# ET6801 register map
Vendor: ETMCU Inc.; File version: v0.0.1
CPU: CM7 r2p1, little endian, MPU, FPU, I-cache, D-cache, ITCM, DTCM, 4 interrupt priority bits
Registers are 32-bit, read-write, reset 0x0 unless marked. A register's access mark holds for its fields unless they carry their own. Offsets are from the block's base; [hi:lo] are bit positions; 'fields as' and 'values as' point back to an identical list.

## CORDIC — Provide an overview of the purpose and functionality of the peripheral: cordic_cfg
Base 0x50000000
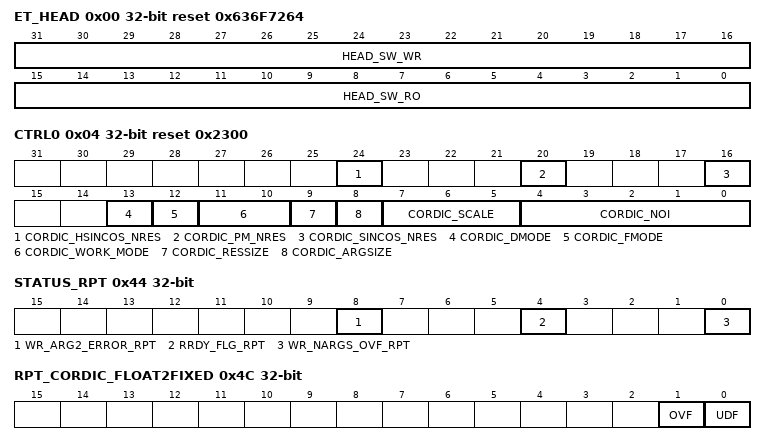
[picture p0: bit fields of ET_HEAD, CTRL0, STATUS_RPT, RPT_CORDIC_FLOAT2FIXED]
0x00 ET_HEAD reset 0x636F7264
  [31:16] HEAD_SW_WR — 软件测试读写寄存器，硬件无访问
  [15:0] HEAD_SW_RO ro — 软件只读上报寄存器，硬件无访问,CORD的ASICII 码表示
0x04 CTRL0 reset 0x2300
  [24] CORDIC_HSINCOS_NRES — 配置HSINCOS时，读取变量选择： 1'b0:hsin/cos任意读取其中之一； 1'b1: 两个结果均读取，hsin/hcos
  [20] CORDIC_PM_NRES — 配置PM时，读取变量选择： 1'b0:phase/moduls任意读取其中之一； 1'b1: 两个结果均读取，phase/moduls
  [16] CORDIC_SINCOS_NRES — 配置SINCOS时，读取变量选择： 1'b0:sin/cos任意读取其中之一； 1'b1: 两个结果均读取，sin/cos
  [13] CORDIC_DMODE — CORDIC计算sin/cos时输入的角度范围以及是否需要做归一化处理： 1'b1：输入的角度范围为[-2pi, +2pi]，软件不需要做归一化处理； 1'b0：输入的角度范围为[-1, +1]，软件需要做归一化处理
  [12] CORDIC_FMODE — CORDIC输入是浮点数还是定点数 1'b0：输入为已经处理过的定点数 1'b1：输入为浮点数，在cordic作定点数转换
  [11:10] CORDIC_WORK_MODE — CORDIC函数选择寄存器： 2'b00:中断模式 2'b01:轮询模式 2'b10:零开销模式 2'b11:DMA搬运模式
  [9] CORDIC_RESSIZE — CORDIC输出结果格式选择寄存器： 1'b0：输出结果格式为16bit 1'b1：输出结果格式为32bit 注：选择输出结果格式为16bit，当函数选择为余弦、正弦、相位、幅度、双曲余弦、双曲正弦时，cordic_res1_rpt寄存器输出两个结果，高16bit为结果2、低16bit为结果1，其余函数低16bit为结果1，高16bit为全0
  [8] CORDIC_ARGSIZE — CORDIC输入变量格式选择寄存器： 1'b0：输入变量格式为16bit 1'b1：输入变量格式为32bit 注：选择输入变量格式为16bit，当函数选择为余弦、正弦、相位、幅度、反正切、双曲余弦、双曲正弦时，cordic_res1_rpt寄存器输出两个结果，高16bit为变量2、低16bit为变量1，其余函数低16bit为变量1，高16bit不关注
  [7:5] CORDIC_SCALE — CORDIC计算比例系数寄存器，表示对输入值x做运算 注：当函数选择为余弦、正弦、相位、幅度时，cfg_cordic_scale不生效，其余函数按照《CORDIC模块LRS设计文档》第1.2.3章节CORDIC函数描述进行配置
  [4:0] CORDIC_NOI — CORDIC迭代周期数选择寄存器，迭代周期数为配置值+1。 注：当迭代周期数大于MAX_ITER_CYC（模块支持最大迭代周期数）时，自动按照MAX_ITER_CYC迭代次数进行迭代
0x08 SINCOS_CAL
  [31:0] DATA — CORDIC单独计算sin/cos输入变量配置寄存器。仅在cfg_cordic_seprtfunc_mode为1时生效;固定配置一次角度，结果同时包含sin/cos
0x0C PM_CAL
  [31:0] DATA — CORDIC单独计算phase/modulus输入变量配置寄存器。仅在cfg_cordic_seprtfunc_mode为1时生效。计算时需要连续输入两个xy坐标值，或者在精度要求不高的情况下输入一次q1.15拼接的xy坐标值
0x10 ARCTAN_CAL
  [31:0] DATA — CORDIC单独计算arctan输入变量配置寄存器。仅在cfg_cordic_seprtfunc_mode为1时生效
0x14 HSINCOS_CAL
  [31:0] DATA — CORDIC单独计算hsin/hcos输入变量配置寄存器。仅在cfg_cordic_seprtfunc_mode为1时生效;固定配置一次角度，结果同时包含sin/cos
0x18 HARCTAN_CAL
  [31:0] DATA — CORDIC单独计算arctanh输入变量配置寄存器。仅在cfg_cordic_seprtfunc_mode为1时生效
0x1C EX_CAL
  [31:0] DATA — CORDIC单独计算ex输入变量配置寄存器。仅在cfg_cordic_seprtfunc_mode为1时生效
0x20 LN_CAL
  [31:0] DATA — CORDIC单独计算ln输入变量配置寄存器。仅在cfg_cordic_seprtfunc_mode为1时生效
0x24 SQRT_CAL
  [31:0] DATA — CORDIC单独计算sqrt输入变量配置寄存器。仅在cfg_cordic_seprtfunc_mode为1时生效
0x28 TAN_CAL
  fields as SQRT_CAL
0x2C INT_EN
  [2:0] CORDIC_INT_EN — 1表示使能CORDIC逻辑中断;0 取消使能 bit2: 计算pm第二变量输入错误但也触发了迭代 bit1: 计算迭代完成 bit0: 写入参数数量溢出
0x30 INT_MASK
  [2:0] CORDIC_INT_MASK — 1表示屏蔽CORDIC逻辑中断;0 取消屏蔽 bit2: 计算pm第二变量输入错误但也触发了迭代 bit1: 计算迭代完成 bit0: 写入参数数量溢出
0x34 INT_FORCE_IND
  [2:0] CORDIC_INT_FORCE_IND — 1表示强制产生相应的测试中断，硬件自清零 bit2: 计算pm第二变量输入错误但也触发了迭代 bit1: 计算迭代完成 bit0: 写入参数数量溢出
0x38 INT_CLR
  [2:0] CORDIC_INT_CLR — 1表示清除相应的中断状态，硬件自清零 bit2: 计算pm第二变量输入错误但也触发了迭代 bit1: 计算迭代完成 bit0: 写入参数数量溢出
0x3C INT_RAW_RPT ro
  [2:0] CORDIC_INT_RAW_RPT — 中断MASK前RAW 中断状态上报 bit2: 计算pm第二变量输入错误但也触发了迭代 bit1: 计算迭代完成 bit0: 写入参数数量溢出
0x40 INT_STATUS_RPT ro
  [2:0] CORDIC_INT_STATUS_RPT — 中断MASK后中断状态上报 bit2: 计算pm第二变量输入错误但也触发了迭代 bit1: 计算迭代完成 bit0: 写入参数数量溢出
0x44 STATUS_RPT
  [8] WR_ARG2_ERROR_RPT — 计算pm时，没有正确输入第二个参数。软件写1清。
  [4] RRDY_FLG_RPT — CORDIC计算完成结果上报中断信号状态上报，软件写1清
  [0] WR_NARGS_OVF_RPT — 写入变量数溢出告警，软件写1清
0x48 WR_NARGS_CNT_RPT ro
  [1:0] WR_NARGS_CNT_RPT — 当前写入变量数计数信号状态上报
0x4C RPT_CORDIC_FLOAT2FIXED
  [1] OVF — CORDIC浮点数转定点数overflow上报，出现overflow后该bit一直拉高直到软件写1清；
  [0] UDF — CORDIC浮点数转定点数underflow上报，出现underflow后该bit一直拉高直到软件写1清；
0x50 RES1_RPT ro
  [31:0] CORDIC_RES1_RPT — CORDIC计算结果1信号上报
0x54 RES2_RPT ro
  [31:0] CORDIC_RES2_RPT — CORDIC计算结果2信号上报
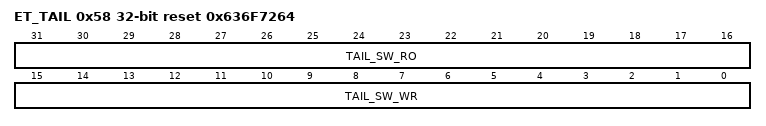
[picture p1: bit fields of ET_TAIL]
0x58 ET_TAIL reset 0x636F7264
  [31:16] TAIL_SW_RO ro — 软件只读硬件上报寄存器
  [15:0] TAIL_SW_WR — 软件测试读写寄存器，硬件无访问
